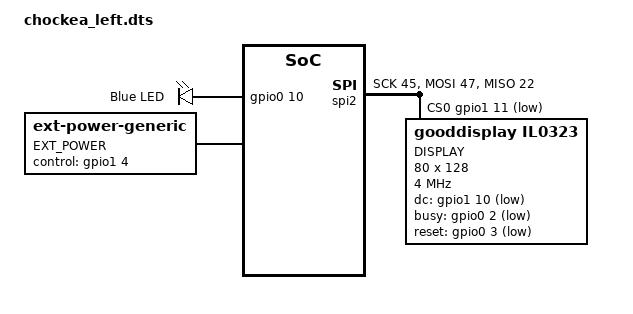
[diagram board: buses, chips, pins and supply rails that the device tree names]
/*
*
* Copyright (c) 2021 Darryl deHaan
* SPDX-License-Identifier: MIT
*
*/

#include "chockea.dtsi"
/ {

leds {
  compatible = "gpio-leds";
  blue_led: led_0 {
    gpios = <&gpio0 10 GPIO_ACTIVE_HIGH>;
    label = "Blue LED";
  };
};
ext-power {
    compatible = "zmk,ext-power-generic";
    label = "EXT_POWER";
    control-gpios = <&gpio1 4 GPIO_ACTIVE_HIGH>;
    init-delay-ms = <50>;
  };
kscan0: kscan {
    col-gpios
        = <&gpio0 23  GPIO_ACTIVE_HIGH>
        , <&gpio0 30   GPIO_ACTIVE_HIGH>
        , <&gpio0 31   GPIO_ACTIVE_HIGH>
        , <&gpio0 19   GPIO_ACTIVE_HIGH>
        , <&gpio0 21   GPIO_ACTIVE_HIGH>
        , <&gpio0 4  GPIO_ACTIVE_HIGH>
        ;
    row-gpios
        = <&gpio1 2 (GPIO_ACTIVE_HIGH | GPIO_PULL_DOWN)>
        , <&gpio1 1  (GPIO_ACTIVE_HIGH | GPIO_PULL_DOWN)>
        , <&gpio1 3  (GPIO_ACTIVE_HIGH | GPIO_PULL_DOWN)>
        , <&gpio1 0  (GPIO_ACTIVE_HIGH | GPIO_PULL_DOWN)>
        , <&gpio0 12  (GPIO_ACTIVE_HIGH | GPIO_PULL_DOWN)>
        ;
        };
    };



&spi2  {
	status = "okay";
	compatible = "nordic,nrf-spim";
	sck-pin = <45>;
	mosi-pin = <47>;
	miso-pin = <22>;
	cs-gpios = <&gpio1 11 GPIO_ACTIVE_LOW>;

	epd: il0323@0 {
		compatible = "gooddisplay,il0323";
		reg =  <0>;
		label = "DISPLAY";
		width = <80>;
		height = <128>;
		spi-max-frequency = <4000000>;
		dc-gpios = <&gpio1 10 GPIO_ACTIVE_LOW>;
		busy-gpios = <&gpio0 2 GPIO_ACTIVE_LOW>;
		reset-gpios = <&gpio0 3 GPIO_ACTIVE_LOW>;
		pwr = [03 00 26 26];
		//softstart = [17 17 17 17];
		cdi = <0xd2>;
		tcon = <0x22>;
	};
};
